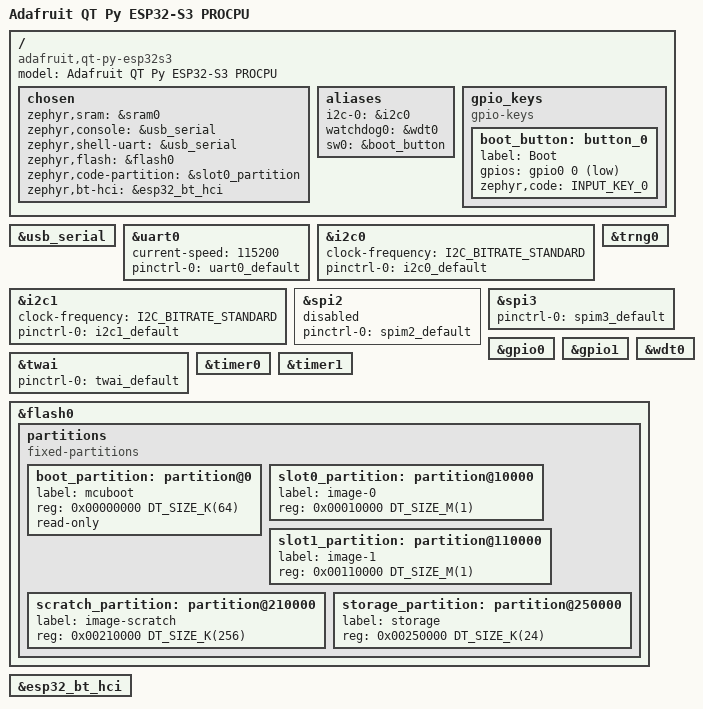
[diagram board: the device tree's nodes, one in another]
/dts-v1/;

#include <espressif/esp32s3/esp32s3_mini_n4r2.dtsi>
#include "adafruit_qt_py_esp32s3-pinctrl.dtsi"
#include "adafruit_qt_py_connector.dtsi"
#include <zephyr/dt-bindings/input/input-event-codes.h>

/ {
	model = "Adafruit QT Py ESP32-S3 PROCPU";
	compatible = "adafruit,qt-py-esp32s3";

	chosen {
		zephyr,sram = &sram0;
		zephyr,console = &usb_serial;
		zephyr,shell-uart = &usb_serial;
		zephyr,flash = &flash0;
		zephyr,code-partition = &slot0_partition;
		zephyr,bt-hci = &esp32_bt_hci;
	};

	aliases {
		i2c-0 = &i2c0;
		watchdog0 = &wdt0;
		sw0 = &boot_button;
	};

	gpio_keys {
		compatible = "gpio-keys";
		boot_button: button_0 {
			label = "Boot";
			gpios = <&gpio0 0 (GPIO_PULL_UP | GPIO_ACTIVE_LOW)>;
			zephyr,code = <INPUT_KEY_0>;
		};
	};
};

&usb_serial {
	status = "okay";
};

&uart0 {
	status = "okay";
	current-speed = <115200>;
	pinctrl-0 = <&uart0_default>;
	pinctrl-names = "default";
};

&i2c0 {
	status = "okay";
	clock-frequency = <I2C_BITRATE_STANDARD>;
	pinctrl-0 = <&i2c0_default>;
	pinctrl-names = "default";
};

/* STEMMA QT Connector */
&i2c1 {
	status = "okay";
	clock-frequency = <I2C_BITRATE_STANDARD>;
	pinctrl-0 = <&i2c1_default>;
	pinctrl-names = "default";
};

&trng0 {
	status = "okay";
};

&spi2 {
	#address-cells = <1>;
	#size-cells = <0>;
	status = "disabled";
	pinctrl-0 = <&spim2_default>;
	pinctrl-names = "default";
};

&spi3 {
	#address-cells = <1>;
	#size-cells = <0>;
	status = "okay";
	pinctrl-0 = <&spim3_default>;
	pinctrl-names = "default";
};

&gpio0 {
	status = "okay";
};

&gpio1 {
	status = "okay";
};

&wdt0 {
	status = "okay";
};

&twai {
	pinctrl-0 = <&twai_default>;
	pinctrl-names = "default";
};
 
&timer0 {
	status = "okay";
};

&timer1 {
	status = "okay";
};

&flash0 {
	status = "okay";
	partitions {
		compatible = "fixed-partitions";
		#address-cells = <1>;
		#size-cells = <1>;

		boot_partition: partition@0 {
			label = "mcuboot";
			reg = <0x00000000 DT_SIZE_K(64)>;
			read-only;
		};

		slot0_partition: partition@10000 {
			label = "image-0";
			reg = <0x00010000 DT_SIZE_M(1)>;
		};

		slot1_partition: partition@110000 {
			label = "image-1";
			reg = <0x00110000 DT_SIZE_M(1)>;
		};

		scratch_partition: partition@210000 {
			label = "image-scratch";
			reg = <0x00210000 DT_SIZE_K(256)>;
		};

		storage_partition: partition@250000 {
			label = "storage";
			reg = <0x00250000 DT_SIZE_K(24)>;
		};
	};
};

&esp32_bt_hci {
	status = "okay";
};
